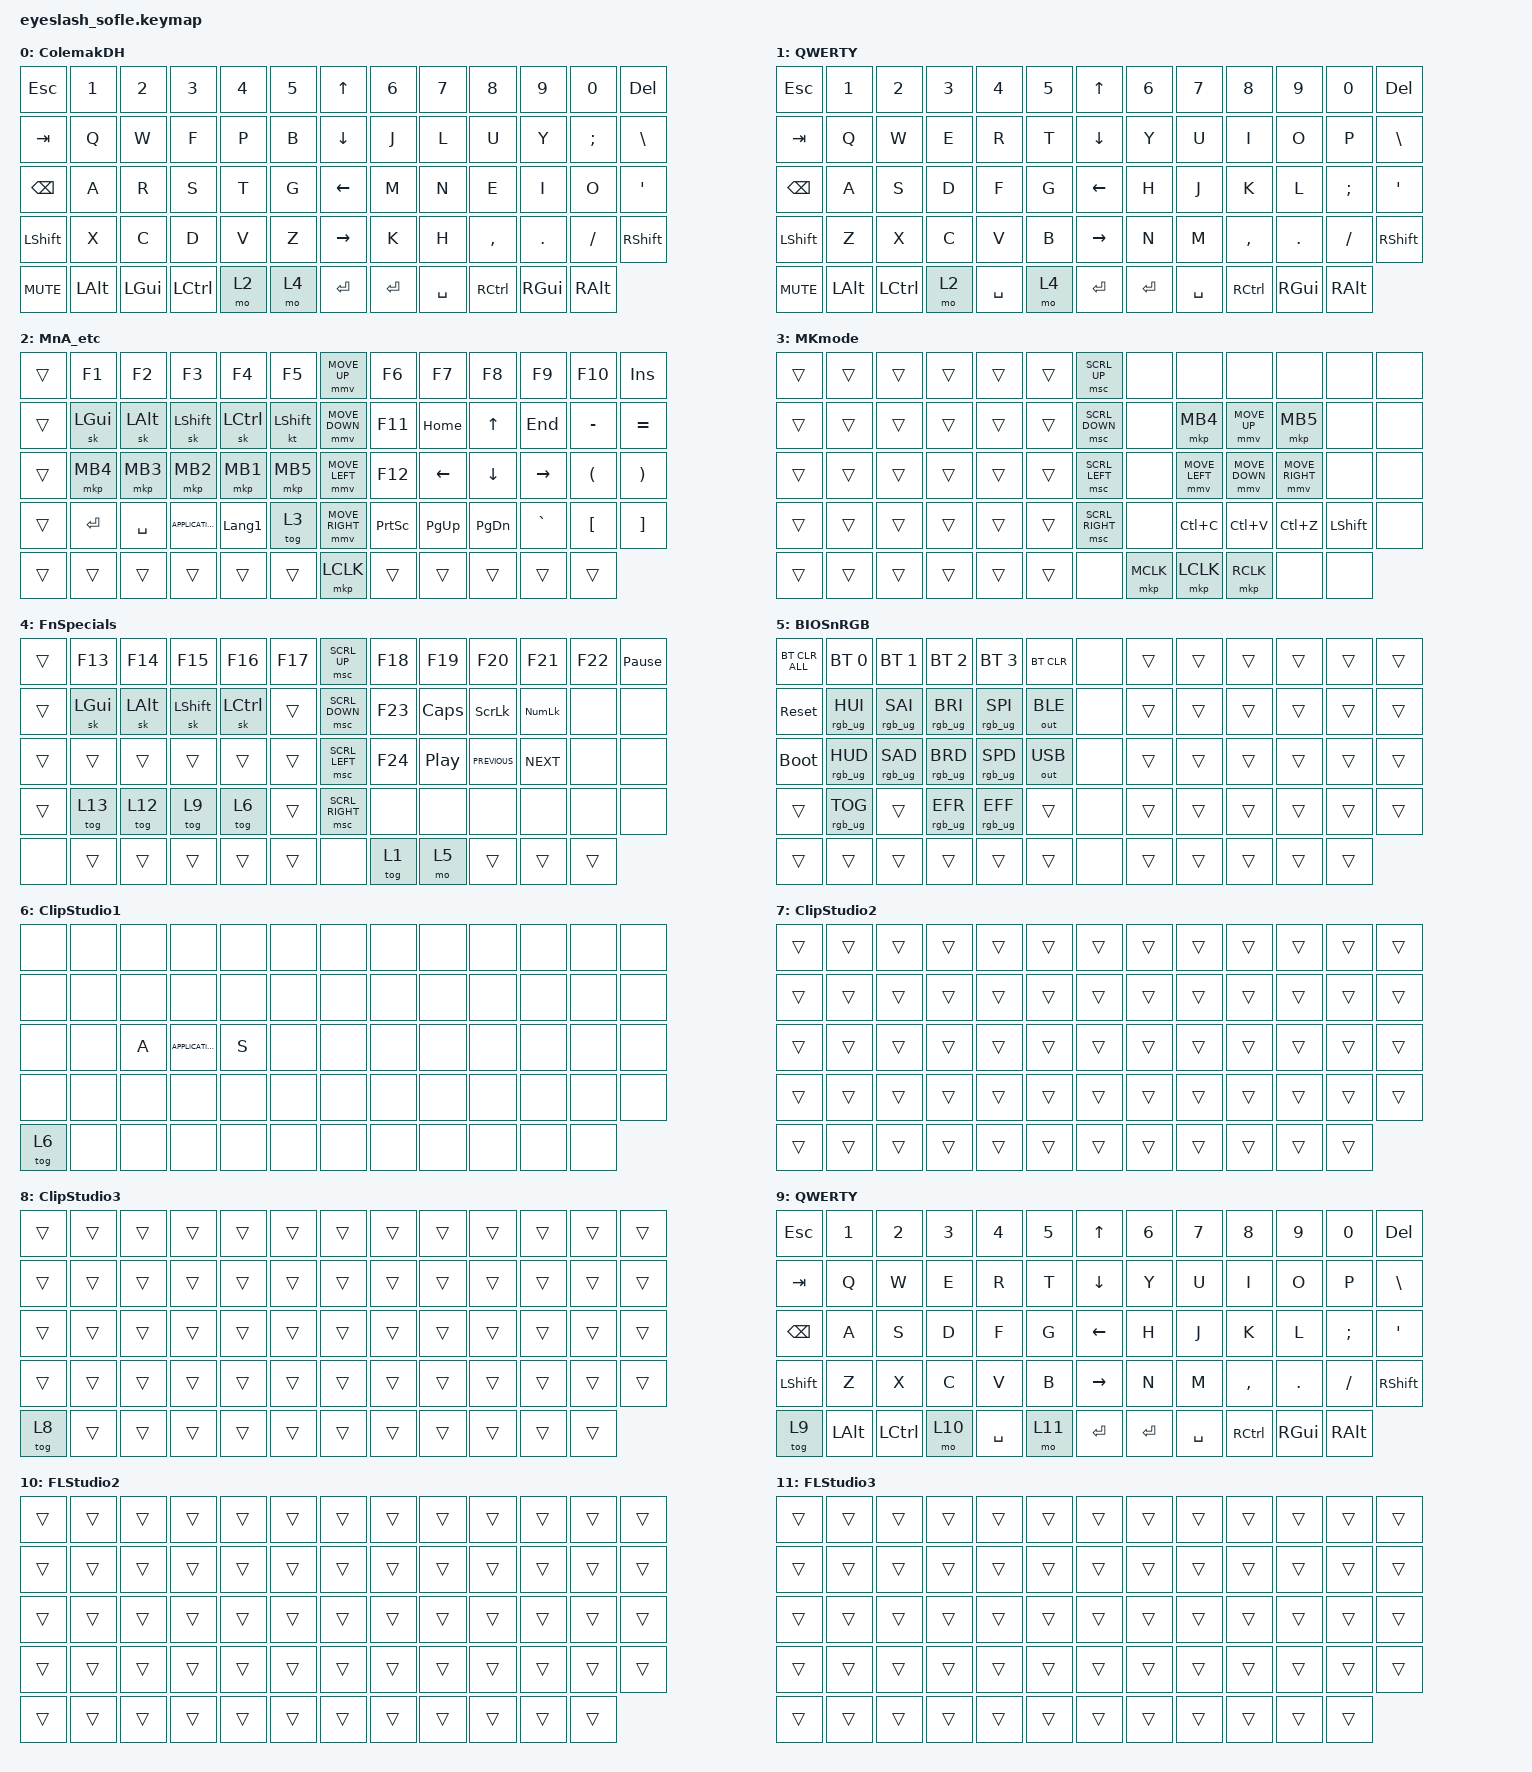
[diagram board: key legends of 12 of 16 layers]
#define ZMK_POINTING_DEFAULT_MOVE_VAL 1200  // 600
#define ZMK_POINTING_DEFAULT_SCRL_VAL 25   // 10

#include <input/processors.dtsi>
#include <zephyr/dt-bindings/input/input-event-codes.h>
#include <behaviors.dtsi>
#include <dt-bindings/zmk/bt.h>
#include <dt-bindings/zmk/keys.h>
#include <dt-bindings/zmk/outputs.h>
#include <dt-bindings/zmk/pointing.h>
#include <dt-bindings/zmk/rgb.h>

&mmv_input_listener { input-processors = <&zip_xy_scaler 2 1>; };

&msc_input_listener { input-processors = <&zip_scroll_scaler 2 1>; };

&msc {
    acceleration-exponent = <1>;      // 0
    time-to-max-speed-ms = <300>;       // 300
    delay-ms = <0>;                   // 0
    trigger-period-ms = <12>;
};

&mmv {
    time-to-max-speed-ms = <750>;
    acceleration-exponent = <1>;
    trigger-period-ms = <12>;
    delay-ms = <0>;
};

&soft_off { hold-time-ms = <2000>; };

/ {
    scroll_encoder: scroll_encoder {
        compatible = "zmk,behavior-sensor-rotate";
        #sensor-binding-cells = <0>;
        bindings = <&msc_for_encoder MOVE_UP>, <&msc_for_encoder MOVE_DOWN>;

        tap-ms = <25>;
        label = "SCROLL_ENCODER";
    };

    scroll_behavior_lr: scroll_behavior_lr {
        compatible = "zmk,behavior-sensor-rotate";
        #sensor-binding-cells = <0>;
        bindings = <&msc_for_encoder MOVE_LEFT>, <&msc_for_encoder MOVE_RIGHT>;

        tap-ms = <25>;
        label = "SCROLL_BEHAVIOR_LR";
    };

    msc_for_encoder: msc_for_encoder {
        compatible = "zmk,behavior-input-two-axis";
        label = "MSC_FOR_ENCODER";
        #binding-cells = <1>;
        x-input-code = <6>;
        y-input-code = <8>;
        time-to-max-speed-ms = <1>;
        trigger-period-ms = <1>;
        acceleration-exponent = <0>;
        delay-ms = <0>;
    };

    behaviors {
    };

    combos {
        compatible = "zmk,combos";

        softoff {
            bindings = <&soft_off>;
            key-positions = <14 28 40>;
        };
    };

    keymap {
        compatible = "zmk,keymap";

        ColemakDH {
            bindings = <
&kp ESC        &kp N1        &kp N2        &kp N3            &kp N4  &kp N5    &kp UP_ARROW     &kp N6     &kp N7     &kp N8             &kp N9         &kp N0         &kp DELETE
&kp TAB        &kp Q         &kp W         &kp F             &kp P   &kp B     &kp DOWN_ARROW   &kp J      &kp L      &kp U              &kp Y          &kp SEMICOLON  &kp BSLH
&kp BACKSPACE  &kp A         &kp R         &kp S             &kp T   &kp G     &kp LEFT_ARROW   &kp M      &kp N      &kp E              &kp I          &kp O          &kp APOS
&kp LSHFT      &kp X         &kp C         &kp D             &kp V   &kp Z     &kp RIGHT_ARROW  &kp K      &kp H      &kp COMMA          &kp DOT        &kp FSLH       &kp RIGHT_SHIFT
&kp C_MUTE     &kp LEFT_ALT  &kp LEFT_GUI  &kp LEFT_CONTROL  &mo 2   &mo 4     &kp ENTER        &kp ENTER  &kp SPACE  &kp RIGHT_CONTROL  &kp RIGHT_GUI  &kp RIGHT_ALT
            >;

            sensor-bindings = <&inc_dec_kp C_VOLUME_UP C_VOL_DN>;
            display-name = "ColemakDH";
        };

        QWERTY {
            display-name = "QWERTY";
            bindings = <
&kp ESC        &kp N1        &kp N2     &kp N3  &kp N4     &kp N5    &kp UP_ARROW     &kp N6     &kp N7     &kp N8             &kp N9         &kp N0         &kp DELETE
&kp TAB        &kp Q         &kp W      &kp E   &kp R      &kp T     &kp DOWN_ARROW   &kp Y      &kp U      &kp I              &kp O          &kp P          &kp BSLH
&kp BACKSPACE  &kp A         &kp S      &kp D   &kp F      &kp G     &kp LEFT_ARROW   &kp H      &kp J      &kp K              &kp L          &kp SEMI       &kp APOS
&kp LSHFT      &kp Z         &kp X      &kp C   &kp V      &kp B     &kp RIGHT_ARROW  &kp N      &kp M      &kp COMMA          &kp DOT        &kp FSLH       &kp RIGHT_SHIFT
&kp C_MUTE     &kp LEFT_ALT  &kp LCTRL  &mo 2   &kp SPACE  &mo 4     &kp ENTER        &kp ENTER  &kp SPACE  &kp RIGHT_CONTROL  &kp RIGHT_GUI  &kp RIGHT_ALT
            >;

            sensor-bindings = <&inc_dec_kp C_VOLUME_UP C_VOL_DN>;
        };

        MnA_etc {
            bindings = <
&trans  &kp F1        &kp F2        &kp F3             &kp F4            &kp F5            &mmv MOVE_UP     &kp F6           &kp F7     &kp F8         &kp F9     &kp F10               &kp INS
&trans  &sk LEFT_GUI  &sk LEFT_ALT  &sk LEFT_SHIFT     &sk LEFT_CONTROL  &kt LEFT_SHIFT    &mmv MOVE_DOWN   &kp F11          &kp HOME   &kp UP         &kp END    &kp MINUS             &kp EQUAL
&trans  &mkp MB4      &mkp MB3      &mkp MB2           &mkp MB1          &mkp MB5          &mmv MOVE_LEFT   &kp F12          &kp LEFT   &kp DOWN       &kp RIGHT  &kp LEFT_PARENTHESIS  &kp RIGHT_PARENTHESIS
&trans  &kp RETURN    &kp SPACE     &kp K_APPLICATION  &kp LANGUAGE_1    &tog 3            &mmv MOVE_RIGHT  &kp PRINTSCREEN  &kp PG_UP  &kp PAGE_DOWN  &kp GRAVE  &kp LEFT_BRACKET      &kp RIGHT_BRACKET
&trans  &trans        &trans        &trans             &trans            &trans            &mkp LCLK        &trans           &trans     &trans         &trans     &trans
            >;

            display-name = "MnA_etc";
            sensor-bindings = <&scroll_encoder>;
        };

        MKmode {
            bindings = <
&trans  &trans  &trans  &trans  &trans  &trans    &msc SCRL_UP     &none      &none           &none           &none            &none           &none
&trans  &trans  &trans  &trans  &trans  &trans    &msc SCRL_DOWN   &none      &mkp MB4        &mmv MOVE_UP    &mkp MB5         &none           &none
&trans  &trans  &trans  &trans  &trans  &trans    &msc SCRL_LEFT   &none      &mmv MOVE_LEFT  &mmv MOVE_DOWN  &mmv MOVE_RIGHT  &none           &none
&trans  &trans  &trans  &trans  &trans  &trans    &msc SCRL_RIGHT  &none      &kp LC(C)       &kp LC(V)       &kp LC(Z)        &kp LEFT_SHIFT  &none
&trans  &trans  &trans  &trans  &trans  &trans    &none            &mkp MCLK  &mkp LCLK       &mkp RCLK       &none            &none
            >;

            label = "MKmode";
        };

        FnSpecials {
            bindings = <
&trans  &kp F13   &kp F14       &kp F15     &kp F16    &kp F17    &msc SCRL_UP     &kp F18  &kp F19           &kp F20         &kp F21         &kp F22  &kp PAUSE_BREAK
&trans  &sk LGUI  &sk LEFT_ALT  &sk LSHIFT  &sk LCTRL  &trans     &msc SCRL_DOWN   &kp F23  &kp CAPSLOCK      &kp SCROLLLOCK  &kp KP_NUMLOCK  &none    &none
&trans  &trans    &trans        &trans      &trans     &trans     &msc SCRL_LEFT   &kp F24  &kp C_PLAY_PAUSE  &kp C_PREVIOUS  &kp C_NEXT      &none    &none
&trans  &tog 13   &tog 12       &tog 9      &tog 6     &trans     &msc SCRL_RIGHT  &none    &none             &none           &none           &none    &none
&none   &trans    &trans        &trans      &trans     &trans     &none            &tog 1   &mo 5             &trans          &trans          &trans
            >;

            display-name = "FnSpecials";
            sensor-bindings = <&scroll_behavior_lr>;
        };

        BIOSnRGB {
            display-name = "BIOSnRGB";
            bindings = <
&bt BT_CLR_ALL  &bt BT_SEL 0     &bt BT_SEL 1     &bt BT_SEL 2     &bt BT_SEL 3     &bt BT_CLR      &none  &trans  &trans  &trans  &trans  &trans  &trans
&sys_reset      &rgb_ug RGB_HUI  &rgb_ug RGB_SAI  &rgb_ug RGB_BRI  &rgb_ug RGB_SPI  &out OUT_BLE    &none  &trans  &trans  &trans  &trans  &trans  &trans
&bootloader     &rgb_ug RGB_HUD  &rgb_ug RGB_SAD  &rgb_ug RGB_BRD  &rgb_ug RGB_SPD  &out OUT_USB    &none  &trans  &trans  &trans  &trans  &trans  &trans
&trans          &rgb_ug RGB_TOG  &trans           &rgb_ug RGB_EFR  &rgb_ug RGB_EFF  &trans          &none  &trans  &trans  &trans  &trans  &trans  &trans
&trans          &trans           &trans           &trans           &trans           &trans          &none  &trans  &trans  &trans  &trans  &trans
            >;

            sensor-bindings = <&scroll_behavior_lr>;
        };

        ClipStudio1 {
            bindings = <
&none   &none  &none  &none              &none  &none    &none  &none  &none  &none  &none  &none  &none
&none   &none  &none  &none              &none  &none    &none  &none  &none  &none  &none  &none  &none
&none   &none  &kp A  &kp K_APPLICATION  &kp S  &none    &none  &none  &none  &none  &none  &none  &none
&none   &none  &none  &none              &none  &none    &none  &none  &none  &none  &none  &none  &none
&tog 6  &none  &none  &none              &none  &none    &none  &none  &none  &none  &none  &none
            >;

            label = "ClipStudio1";
        };

        ClipStudio2 {
            bindings = <
&trans  &trans  &trans  &trans  &trans  &trans    &trans  &trans  &trans  &trans  &trans  &trans  &trans
&trans  &trans  &trans  &trans  &trans  &trans    &trans  &trans  &trans  &trans  &trans  &trans  &trans
&trans  &trans  &trans  &trans  &trans  &trans    &trans  &trans  &trans  &trans  &trans  &trans  &trans
&trans  &trans  &trans  &trans  &trans  &trans    &trans  &trans  &trans  &trans  &trans  &trans  &trans
&trans  &trans  &trans  &trans  &trans  &trans    &trans  &trans  &trans  &trans  &trans  &trans
            >;

            label = "ClipStudio2";
        };

        ClipStudio3 {
            bindings = <
&trans  &trans  &trans  &trans  &trans  &trans    &trans  &trans  &trans  &trans  &trans  &trans  &trans
&trans  &trans  &trans  &trans  &trans  &trans    &trans  &trans  &trans  &trans  &trans  &trans  &trans
&trans  &trans  &trans  &trans  &trans  &trans    &trans  &trans  &trans  &trans  &trans  &trans  &trans
&trans  &trans  &trans  &trans  &trans  &trans    &trans  &trans  &trans  &trans  &trans  &trans  &trans
&tog 8  &trans  &trans  &trans  &trans  &trans    &trans  &trans  &trans  &trans  &trans  &trans
            >;

            label = "ClipStudio3";
        };

        FLStudio1 {
            display-name = "QWERTY";
            bindings = <
&kp ESC        &kp N1        &kp N2     &kp N3  &kp N4     &kp N5    &kp UP_ARROW     &kp N6     &kp N7     &kp N8             &kp N9         &kp N0         &kp DELETE
&kp TAB        &kp Q         &kp W      &kp E   &kp R      &kp T     &kp DOWN_ARROW   &kp Y      &kp U      &kp I              &kp O          &kp P          &kp BSLH
&kp BACKSPACE  &kp A         &kp S      &kp D   &kp F      &kp G     &kp LEFT_ARROW   &kp H      &kp J      &kp K              &kp L          &kp SEMI       &kp APOS
&kp LSHFT      &kp Z         &kp X      &kp C   &kp V      &kp B     &kp RIGHT_ARROW  &kp N      &kp M      &kp COMMA          &kp DOT        &kp FSLH       &kp RIGHT_SHIFT
&tog 9         &kp LEFT_ALT  &kp LCTRL  &mo 10  &kp SPACE  &mo 11    &kp ENTER        &kp ENTER  &kp SPACE  &kp RIGHT_CONTROL  &kp RIGHT_GUI  &kp RIGHT_ALT
            >;

            sensor-bindings = <&inc_dec_kp C_VOLUME_UP C_VOL_DN>;
            label = "FLStudio1";
        };

        FLStudio2 {
            bindings = <
&trans  &trans  &trans  &trans  &trans  &trans    &trans  &trans  &trans  &trans  &trans  &trans  &trans
&trans  &trans  &trans  &trans  &trans  &trans    &trans  &trans  &trans  &trans  &trans  &trans  &trans
&trans  &trans  &trans  &trans  &trans  &trans    &trans  &trans  &trans  &trans  &trans  &trans  &trans
&trans  &trans  &trans  &trans  &trans  &trans    &trans  &trans  &trans  &trans  &trans  &trans  &trans
&trans  &trans  &trans  &trans  &trans  &trans    &trans  &trans  &trans  &trans  &trans  &trans
            >;

            label = "FLStudio2";
        };

        FLStudio3 {
            bindings = <
&trans  &trans  &trans  &trans  &trans  &trans    &trans  &trans  &trans  &trans  &trans  &trans  &trans
&trans  &trans  &trans  &trans  &trans  &trans    &trans  &trans  &trans  &trans  &trans  &trans  &trans
&trans  &trans  &trans  &trans  &trans  &trans    &trans  &trans  &trans  &trans  &trans  &trans  &trans
&trans  &trans  &trans  &trans  &trans  &trans    &trans  &trans  &trans  &trans  &trans  &trans  &trans
&trans  &trans  &trans  &trans  &trans  &trans    &trans  &trans  &trans  &trans  &trans  &trans
            >;

            label = "FLStudio3";
        };

        Main3 {
            bindings = <
&trans   &trans  &trans  &trans  &trans  &trans    &trans  &trans  &trans  &trans  &trans  &trans  &trans
&trans   &trans  &trans  &trans  &trans  &trans    &trans  &trans  &trans  &trans  &trans  &trans  &trans
&trans   &trans  &trans  &trans  &trans  &trans    &trans  &trans  &trans  &trans  &trans  &trans  &trans
&trans   &trans  &trans  &trans  &trans  &trans    &trans  &trans  &trans  &trans  &trans  &trans  &trans
&tog 12  &trans  &trans  &trans  &trans  &trans    &trans  &trans  &trans  &trans  &trans  &trans
            >;
        };

        Main4 {
            bindings = <
&trans  &trans  &trans  &trans  &trans  &trans    &trans  &trans  &trans  &trans  &trans  &trans  &trans
&trans  &trans  &trans  &trans  &trans  &trans    &trans  &trans  &trans  &trans  &trans  &trans  &trans
&trans  &trans  &trans  &trans  &trans  &trans    &trans  &trans  &trans  &trans  &trans  &trans  &trans
&trans  &trans  &trans  &trans  &trans  &trans    &trans  &trans  &trans  &trans  &trans  &trans  &trans
&trans  &trans  &trans  &trans  &trans  &trans    &trans  &trans  &trans  &trans  &trans  &trans
            >;
        };

        layer_14 {
            bindings = <
&trans  &trans  &trans  &trans  &trans  &trans    &trans  &trans  &trans  &trans  &trans  &trans  &trans
&trans  &trans  &trans  &trans  &trans  &trans    &trans  &trans  &trans  &trans  &trans  &trans  &trans
&trans  &trans  &trans  &trans  &trans  &trans    &trans  &trans  &trans  &trans  &trans  &trans  &trans
&trans  &trans  &trans  &trans  &trans  &trans    &trans  &trans  &trans  &trans  &trans  &trans  &trans
&trans  &trans  &trans  &trans  &trans  &trans    &trans  &trans  &trans  &trans  &trans  &trans
            >;
        };

        layer_15 {
            bindings = <
&trans  &trans  &trans  &trans  &trans  &trans    &trans  &trans  &trans  &trans  &trans  &trans  &trans
&trans  &trans  &trans  &trans  &trans  &trans    &trans  &trans  &trans  &trans  &trans  &trans  &trans
&trans  &trans  &trans  &trans  &trans  &trans    &trans  &trans  &trans  &trans  &trans  &trans  &trans
&trans  &trans  &trans  &trans  &trans  &trans    &trans  &trans  &trans  &trans  &trans  &trans  &trans
&trans  &trans  &trans  &trans  &trans  &trans    &trans  &trans  &trans  &trans  &trans  &trans
            >;
        };
    };
};
